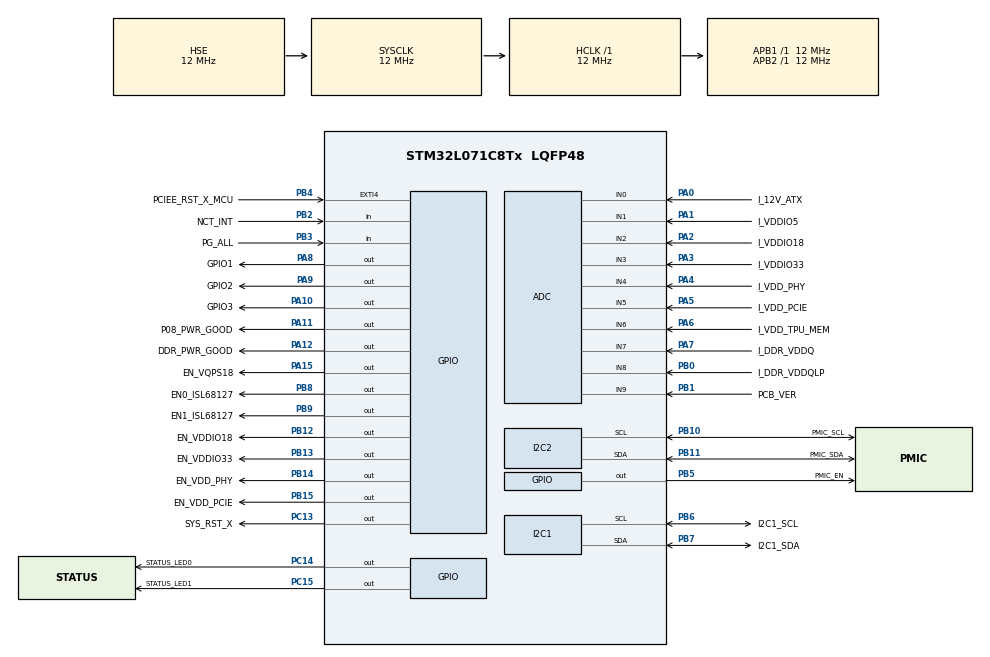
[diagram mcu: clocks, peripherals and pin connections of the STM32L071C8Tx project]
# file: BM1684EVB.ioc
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Mcu.Family=STM32L0
PA11.GPIO_Speed=GPIO_SPEED_FREQ_LOW
PA6.Mode=IN6
PH0-OSC_IN.Signal=RCC_OSC_IN
PB10.Mode=I2C
PB4.GPIO_ModeDefaultEXTI=GPIO_MODE_IT_FALLING
PA10.GPIO_PuPd=GPIO_PULLDOWN
PB14.GPIO_Label=EN_VDD_PHY
I2C2.Timing=0x40000A0B
PA0.GPIO_Label=I_12V_ATX
PB9.GPIO_ModeDefaultOutputPP=GPIO_MODE_OUTPUT_PP
VP_RTC_VS_RTC_Activate.Mode=RTC_Enabled
PA6.GPIO_Label=I_VDD_TPU_MEM
PB0.GPIO_Label=I_DDR_VDDQLP
PB6.GPIO_Label=I2C1_SCL
PA11.GPIO_PuPd=GPIO_PULLDOWN
PC13.GPIO_Label=SYS_RST_X
PB13.GPIO_Label=EN_VDDIO33
PB11.Signal=I2C2_SDA
PB13.Signal=GPIO_Output
PB15.Signal=GPIO_Output
PB15.PinState=GPIO_PIN_RESET
PC15-OSC32_OUT.GPIO_Label=STATUS_LED1
RCC.SYSCLKSource=RCC_SYSCLKSOURCE_HSE
ProjectManager.StackSize=0x400
NVIC.I2C1_IRQn=true\:0\:0\:false\:false\:true\:true\:true
PA12.GPIO_ModeDefaultOutputPP=GPIO_MODE_OUTPUT_PP
ADC.DiscontinuousConvMode=ENABLE
PA15.GPIO_Label=EN_VQPS18
PA12.Signal=GPIO_Output
PA4.Mode=IN4
PC13.GPIO_ModeDefaultOutputPP=GPIO_MODE_OUTPUT_OD
PA10.PinState=GPIO_PIN_RESET
RCC.HCLKFreq_Value=12000000
RCC.APB2TimFreq_Value=12000000
PB6.Signal=I2C1_SCL
PB13.GPIO_ModeDefaultOutputPP=GPIO_MODE_OUTPUT_PP
PB12.PinState=GPIO_PIN_RESET
PB6.Mode=I2C
PB15.GPIO_ModeDefaultOutputPP=GPIO_MODE_OUTPUT_PP
RCC.AHBFreq_Value=12000000
PH0-OSC_IN.Mode=HSE-External-Oscillator
PA12.PinState=GPIO_PIN_RESET
RCC.HSE_VALUE=12000000
PB2.Signal=GPIO_Input
PB12.GPIO_ModeDefaultOutputPP=GPIO_MODE_OUTPUT_PP
PB12.GPIO_Label=EN_VDDIO18
PA11.GPIO_ModeDefaultOutputPP=GPIO_MODE_OUTPUT_PP
LPTIM1.ClockPrescaler=LPTIM_PRESCALER_DIV128
PB3.GPIO_PuPd=GPIO_NOPULL
PA14.Mode=Serial_Wire
PB1.GPIO_Label=PCB_VER
PA10.GPIO_Label=GPIO3
PA0.Mode=IN0
PC13.GPIO_PuPd=GPIO_PULLUP
PB8.PinState=GPIO_PIN_RESET
PB7.Signal=I2C1_SDA
PA8.Signal=GPIO_Output
PA8.GPIO_ModeDefaultOutputPP=GPIO_MODE_OUTPUT_PP
PC15-OSC32_OUT.PinState=GPIO_PIN_RESET
PA15.GPIO_ModeDefaultOutputPP=GPIO_MODE_OUTPUT_PP
PB2.GPIO_PuPd=GPIO_NOPULL
PA0.Signal=ADC_IN0
PC14-OSC32_IN.GPIO_Speed=GPIO_SPEED_FREQ_LOW
PH1-OSC_OUT.Mode=HSE-External-Oscillator
PB7.GPIO_Label=I2C1_SDA
Mcu.Package=LQFP48
PB9.Signal=GPIO_Output
PB14.GPIO_PuPd=GPIO_PULLDOWN
PB1.Signal=ADC_IN9
PA6.Signal=ADC_IN6
PC14-OSC32_IN.PinState=GPIO_PIN_RESET
PB15.GPIO_PuPd=GPIO_PULLDOWN
PA2.GPIO_Label=I_VDDIO18
VP_LPTIM1_VS_LPTIM_counterModeInternalClock.Mode=Counts__internal_clock_event_00
PA10.Signal=GPIO_Output
PB9.GPIO_PuPd=GPIO_PULLDOWN
PA15.Signal=GPIO_Output
PB8.GPIO_ModeDefaultOutputPP=GPIO_MODE_OUTPUT_PP
PA10.GPIO_Speed=GPIO_SPEED_FREQ_LOW
PB9.GPIO_Speed=GPIO_SPEED_FREQ_LOW
PB5.GPIO_Label=PMIC_EN
PC15-OSC32_OUT.GPIO_ModeDefaultOutputPP=GPIO_MODE_OUTPUT_PP
PC14-OSC32_IN.GPIO_ModeDefaultOutputPP=GPIO_MODE_OUTPUT_PP
RCC.APB1TimFreq_Value=12000000
PC13.GPIO_Speed=GPIO_SPEED_FREQ_LOW
PC14-OSC32_IN.GPIO_Label=STATUS_LED0
PC15-OSC32_OUT.GPIO_Speed=GPIO_SPEED_FREQ_LOW
PA12.GPIO_PuPd=GPIO_PULLDOWN
PA4.GPIO_Label=I_VDD_PHY
PA8.GPIO_Speed=GPIO_SPEED_FREQ_LOW
PB9.GPIO_FM9=__NULL
PA12.GPIO_Speed=GPIO_SPEED_FREQ_LOW
NVIC.EXTI4_15_IRQn=true\:0\:0\:false\:false\:true\:true\:true
PC13.PinState=GPIO_PIN_RESET
PA8.PinState=GPIO_PIN_RESET
PB4.Signal=GPXTI4
PA3.Signal=ADC_IN3
PA5.Mode=IN5
PB3.GPIO_Label=PG_ALL
RCC.MSI_VALUE=2097000
PA7.Mode=IN7
PB9.GPIO_Label=EN1_ISL68127
PB8.GPIO_FM8=__NULL
PC13.Signal=GPIO_Output
PA9.GPIO_Label=GPIO2
PB8.GPIO_PuPd=GPIO_PULLDOWN
PB11.GPIO_Label=PMIC_SDA
PA11.GPIO_Label=P08_PWR_GOOD
PC14-OSC32_IN.Signal=GPIO_Output
ADC.ClockPrescaler=ADC_CLOCK_SYNC_PCLK_DIV1
PA9.GPIO_PuPd=GPIO_PULLDOWN
PA12.GPIO_Label=DDR_PWR_GOOD
I2C1.OwnAddress2=0x68
I2C1.DualAddressMode=I2C_DUALADDRESS_ENABLE
PA3.Mode=IN3
PA13.Signal=SYS_SWDIO
RCC.HSI16_VALUE=16000000
PB8.GPIO_Label=EN0_ISL68127
PA8.GPIO_Label=GPIO1
PB14.PinState=GPIO_PIN_RESET
PB11.Mode=I2C
ProjectManager.TargetToolchain=TrueSTUDIO
PB14.GPIO_Speed=GPIO_SPEED_FREQ_LOW
PB10.GPIO_Label=PMIC_SCL
PA10.GPIO_ModeDefaultOutputPP=GPIO_MODE_OUTPUT_PP
PA9.Signal=GPIO_Output
I2C1.Timing=0x40000A0B
PB13.GPIO_Speed=GPIO_SPEED_FREQ_LOW
PA9.PinState=GPIO_PIN_RESET
PB4.GPIO_PuPd=GPIO_PULLUP
RCC.LSE_VALUE=32768
PC15-OSC32_OUT.Signal=GPIO_Output
PB14.GPIO_ModeDefaultOutputPP=GPIO_MODE_OUTPUT_PP
PA1.Signal=ADC_IN1
PB12.GPIO_Speed=GPIO_SPEED_FREQ_LOW
PB10.Signal=I2C2_SCL
PB14.Signal=GPIO_Output
PA5.Signal=ADC_IN5
PB0.Mode=IN8
board=custom
RCC.VCOOutputFreq_Value=48000000
NVIC.LPTIM1_IRQn=true\:0\:0\:false\:false\:true\:true\:true
PB13.GPIO_PuPd=GPIO_PULLDOWN
PA15.PinState=GPIO_PIN_RESET
RCC.APB2Freq_Value=12000000
PA1.Mode=IN1
PB2.GPIO_Mode=GPIO_MODE_INPUT
I2C1.OwnAddress2Masks=I2C_OA2_MASK02
PB13.PinState=GPIO_PIN_RESET
PB4.GPIO_Label=PCIEE_RST_X_MCU
PB15.GPIO_Label=EN_VDD_PCIE
PB15.GPIO_Speed=GPIO_SPEED_FREQ_LOW
PA1.GPIO_Label=I_VDDIO5
PH1-OSC_OUT.Signal=RCC_OSC_OUT
PC15-OSC32_OUT.GPIO_PuPd=GPIO_PULLUP
PB3.GPIO_Mode=GPIO_MODE_INPUT
PA13.Mode=Serial_Wire
Mcu.Name=STM32L071C8Tx
RCC.LptimClockSelection=RCC_LPTIM1CLKSOURCE_LSI
PA2.Signal=ADC_IN2
I2C1.OwnAddress=0x17
PA9.GPIO_ModeDefaultOutputPP=GPIO_MODE_OUTPUT_PP
PB3.Signal=GPIO_Input
PA4.Signal=ADC_IN4
RCC.SYSCLKFreq_VALUE=12000000
PB5.Signal=GPIO_Output
PA7.GPIO_Label=I_DDR_VDDQ
PA5.GPIO_Label=I_VDD_PCIE
PB5.GPIO_PuPd=GPIO_PULLDOWN
PA15.GPIO_Speed=GPIO_SPEED_FREQ_LOW
PB9.PinState=GPIO_PIN_RESET
PA11.Signal=GPIO_Output
PB7.Mode=I2C
PA14.Signal=SYS_SWCLK
PB2.GPIO_Label=NCT_INT
ProjectManager.HeapSize=0x200
PB1.Mode=IN9
RCC.HSI_VALUE=16000000
PA8.GPIO_PuPd=GPIO_PULLDOWN
PA15.GPIO_PuPd=GPIO_PULLDOWN
PA2.Mode=IN2
PA9.GPIO_Speed=GPIO_SPEED_FREQ_LOW
PB8.Signal=GPIO_Output
PC14-OSC32_IN.GPIO_PuPd=GPIO_PULLUP
PB12.GPIO_PuPd=GPIO_PULLDOWN
PA11.PinState=GPIO_PIN_RESET
RCC.APB1Freq_Value=12000000
PB8.GPIO_Speed=GPIO_SPEED_FREQ_LOW
PB0.Signal=ADC_IN8
ADC.ContinuousConvMode=DISABLE
PB12.Signal=GPIO_Output
PA3.GPIO_Label=I_VDDIO33
PA7.Signal=ADC_IN7

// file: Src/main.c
/* USER CODE BEGIN Header */
/**
  ******************************************************************************
  * @file           : main.c
  * @brief          : Main program body
  ******************************************************************************
  ** This notice applies to any and all portions of this file
  * that are not between comment pairs USER CODE BEGIN and
  * USER CODE END. Other portions of this file, whether
  * inserted by the user or by software development tools
  * are owned by their respective copyright owners.
  *
  * COPYRIGHT(c) 2019 STMicroelectronics
  *
  * Redistribution and use in source and binary forms, with or without modification,
  * are permitted provided that the following conditions are met:
  *   1. Redistributions of source code must retain the above copyright notice,
  *      this list of conditions and the following disclaimer.
  *   2. Redistributions in binary form must reproduce the above copyright notice,
  *      this list of conditions and the following disclaimer in the documentation
  *      and/or other materials provided with the distribution.
  *   3. Neither the name of STMicroelectronics nor the names of its contributors
  *      may be used to endorse or promote products derived from this software
  *      without specific prior written permission.
  *
  * THIS SOFTWARE IS PROVIDED BY THE COPYRIGHT HOLDERS AND CONTRIBUTORS "AS IS"
  * AND ANY EXPRESS OR IMPLIED WARRANTIES, INCLUDING, BUT NOT LIMITED TO, THE
  * IMPLIED WARRANTIES OF MERCHANTABILITY AND FITNESS FOR A PARTICULAR PURPOSE ARE
  * DISCLAIMED. IN NO EVENT SHALL THE COPYRIGHT HOLDER OR CONTRIBUTORS BE LIABLE
  * FOR ANY DIRECT, INDIRECT, INCIDENTAL, SPECIAL, EXEMPLARY, OR CONSEQUENTIAL
  * DAMAGES (INCLUDING, BUT NOT LIMITED TO, PROCUREMENT OF SUBSTITUTE GOODS OR
  * SERVICES; LOSS OF USE, DATA, OR PROFITS; OR BUSINESS INTERRUPTION) HOWEVER
  * CAUSED AND ON ANY THEORY OF LIABILITY, WHETHER IN CONTRACT, STRICT LIABILITY,
  * OR TORT (INCLUDING NEGLIGENCE OR OTHERWISE) ARISING IN ANY WAY OUT OF THE USE
  * OF THIS SOFTWARE, EVEN IF ADVISED OF THE POSSIBILITY OF SUCH DAMAGE.
  *
  ******************************************************************************
  */
/* USER CODE END Header */

#include "main.h"
#include "adc.h"
#include "i2c.h"
#include "lptim.h"
#include "rtc.h"
#include "gpio.h"

/* USER CODE BEGIN Includes */
#include "upgrade.h"
#include "bm_common_func.h"

/* USER CODE END Includes */

/* USER CODE BEGIN PV */
I2C_REGS i2c_regs;
/* USER CODE END PV */

void SystemClock_Config(void);

int main(void)
{
  /* USER CODE BEGIN 1 */
  /* maybe no return */
  setup_stage();

  /* USER CODE END 1 */

  /* MCU Configuration--------------------------------------------------------*/

  /* Reset of all peripherals, Initializes the Flash interface and the Systick. */
  HAL_Init();

  /* Configure the system clock */
  SystemClock_Config();

  /* Initialize all configured peripherals */
  MX_GPIO_Init();
  MX_I2C2_Init();
  MX_I2C1_Init();
  MX_LPTIM1_Init();
  MX_RTC_Init();
  MX_ADC_Init();
  /* USER CODE BEGIN 2 */
  module_init();

  PowerON();
  /* USER CODE END 2 */

  /* Infinite loop */
  while (1)
  {

    /* USER CODE BEGIN 3 */
	cmd_process();

	//get current of ten channels
	Scan_Cuerrent();
	Scan_Voltage();

	//POLL PCIEE_RST STATUS FOR SYS_RST
	poll_pcie_rst();
//	  GET_Current_Voltage();
  }
  /* USER CODE END 3 */
}

void SystemClock_Config(void)
{
  RCC_OscInitTypeDef RCC_OscInitStruct = {0};
  RCC_ClkInitTypeDef RCC_ClkInitStruct = {0};
  RCC_PeriphCLKInitTypeDef PeriphClkInit = {0};

  /** Configure the main internal regulator output voltage
  */
  __HAL_PWR_VOLTAGESCALING_CONFIG(PWR_REGULATOR_VOLTAGE_SCALE1);
  /** Initializes the CPU, AHB and APB busses clocks
  */
  RCC_OscInitStruct.OscillatorType = RCC_OSCILLATORTYPE_LSI|RCC_OSCILLATORTYPE_HSE;
  RCC_OscInitStruct.HSEState = RCC_HSE_ON;
  RCC_OscInitStruct.LSIState = RCC_LSI_ON;
  RCC_OscInitStruct.PLL.PLLState = RCC_PLL_NONE;
  if (HAL_RCC_OscConfig(&RCC_OscInitStruct) != HAL_OK)
  {
    Error_Handler();
  }
  /** Initializes the CPU, AHB and APB busses clocks
  */
  RCC_ClkInitStruct.ClockType = RCC_CLOCKTYPE_HCLK|RCC_CLOCKTYPE_SYSCLK
                              |RCC_CLOCKTYPE_PCLK1|RCC_CLOCKTYPE_PCLK2;
  RCC_ClkInitStruct.SYSCLKSource = RCC_SYSCLKSOURCE_HSE;
  RCC_ClkInitStruct.AHBCLKDivider = RCC_SYSCLK_DIV1;
  RCC_ClkInitStruct.APB1CLKDivider = RCC_HCLK_DIV1;
  RCC_ClkInitStruct.APB2CLKDivider = RCC_HCLK_DIV1;

  if (HAL_RCC_ClockConfig(&RCC_ClkInitStruct, FLASH_LATENCY_0) != HAL_OK)
  {
    Error_Handler();
  }
  PeriphClkInit.PeriphClockSelection = RCC_PERIPHCLK_I2C1|RCC_PERIPHCLK_RTC
                              |RCC_PERIPHCLK_LPTIM1;
  PeriphClkInit.I2c1ClockSelection = RCC_I2C1CLKSOURCE_PCLK1;
  PeriphClkInit.RTCClockSelection = RCC_RTCCLKSOURCE_LSI;
  PeriphClkInit.LptimClockSelection = RCC_LPTIM1CLKSOURCE_LSI;

  if (HAL_RCCEx_PeriphCLKConfig(&PeriphClkInit) != HAL_OK)
  {
    Error_Handler();
  }
}

void Error_Handler(void)
{
}

/************************ (C) COPYRIGHT STMicroelectronics *****END OF FILE****/
